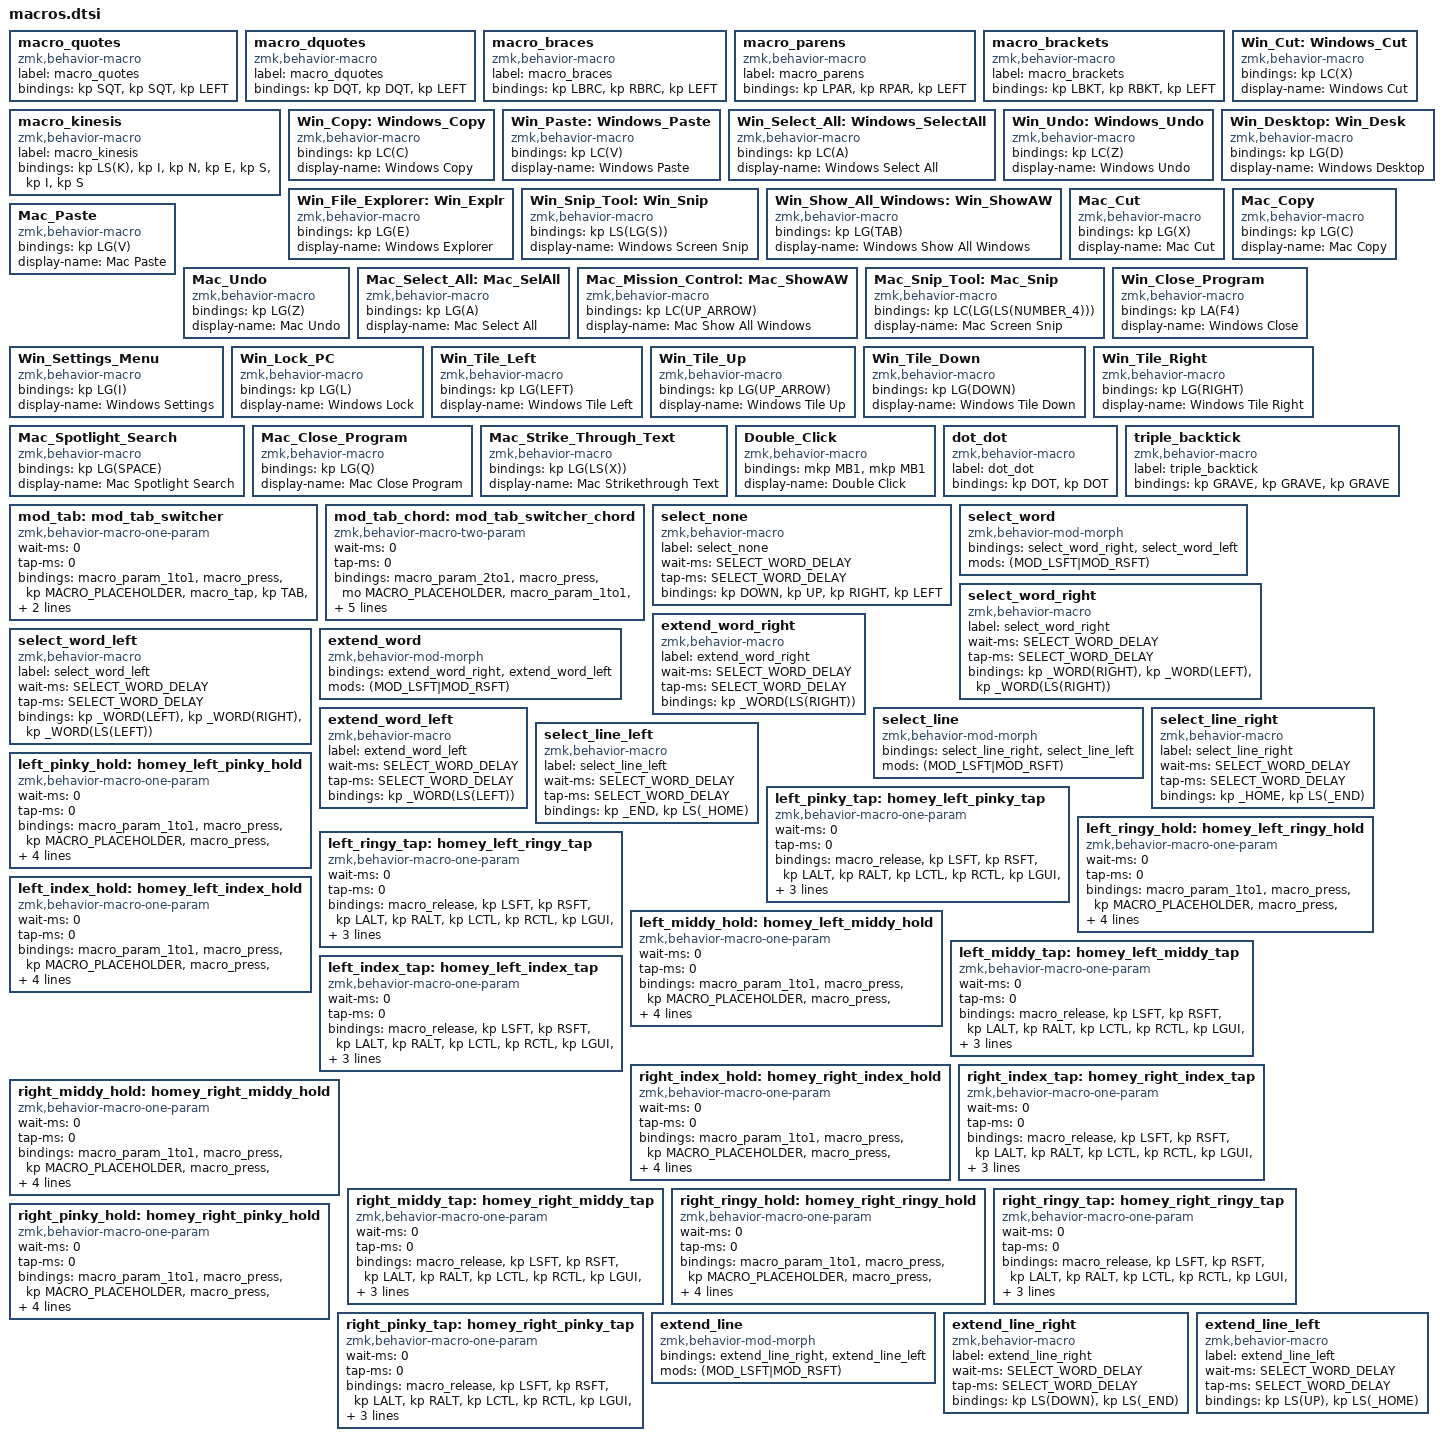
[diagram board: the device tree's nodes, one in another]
  macro_quotes: macro_quotes {
    compatible = "zmk,behavior-macro";
    label = "macro_quotes";
    #binding-cells = <0>;
    bindings = <&kp SQT>, <&kp SQT>, <&kp LEFT>;
  };

  macro_dquotes: macro_dquotes {
    compatible = "zmk,behavior-macro";
    label = "macro_dquotes";
    #binding-cells = <0>;
    bindings = <&kp DQT>, <&kp DQT>, <&kp LEFT>;
  };

  macro_braces: macro_braces {
    compatible = "zmk,behavior-macro";
    label = "macro_braces";
    #binding-cells = <0>;
    bindings = <&kp LBRC>, <&kp RBRC>, <&kp LEFT>;
  };

  macro_parens: macro_parens {
    compatible = "zmk,behavior-macro";
    label = "macro_parens";
    #binding-cells = <0>;
    bindings = <&kp LPAR>, <&kp RPAR>, <&kp LEFT>;
  };

  macro_brackets: macro_brackets {
    compatible = "zmk,behavior-macro";
    label = "macro_brackets";
    #binding-cells = <0>;
    bindings = <&kp LBKT>, <&kp RBKT>, <&kp LEFT>;
  };

  macro_kinesis: macro_kinesis {
    compatible = "zmk,behavior-macro";
    label = "macro_kinesis";
    #binding-cells = <0>;
    bindings = <&kp LS(K)>, <&kp I>, <&kp N>, <&kp E>, <&kp S>, <&kp I>, <&kp S>;
  };

  Win_Cut: Windows_Cut {
    compatible = "zmk,behavior-macro";
    #binding-cells = <0>;
    bindings = <&kp LC(X)>;
    display-name = "Windows Cut";
  };

  Win_Copy: Windows_Copy {
    compatible = "zmk,behavior-macro";
    #binding-cells = <0>;
    bindings = <&kp LC(C)>;
    display-name = "Windows Copy";
  };

  Win_Paste: Windows_Paste {
    compatible = "zmk,behavior-macro";
    #binding-cells = <0>;
    bindings = <&kp LC(V)>;
    display-name = "Windows Paste";
  };

  Win_Select_All: Windows_SelectAll {
      compatible = "zmk,behavior-macro";
      #binding-cells = <0>;
      bindings = <&kp LC(A)>;
      display-name = "Windows Select All";
  };

  Win_Undo: Windows_Undo {
    compatible = "zmk,behavior-macro";
    #binding-cells = <0>;
    bindings = <&kp LC(Z)>;
    display-name = "Windows Undo";
  };

  Win_Desktop: Win_Desk {
    compatible = "zmk,behavior-macro";
    #binding-cells = <0>;
    bindings = <&kp LG(D)>;
    display-name = "Windows Desktop";
  };

  Win_File_Explorer: Win_Explr {
    compatible = "zmk,behavior-macro";
    #binding-cells = <0>;
    bindings = <&kp LG(E)>;
    display-name = "Windows Explorer";
  };

  Win_Snip_Tool: Win_Snip {
    compatible = "zmk,behavior-macro";
    #binding-cells = <0>;
    bindings = <&kp LS(LG(S))>;
    display-name = "Windows Screen Snip";
  };

  Win_Show_All_Windows: Win_ShowAW {
    compatible = "zmk,behavior-macro";
    #binding-cells = <0>;
    bindings = <&kp LG(TAB)>;
    display-name = "Windows Show All Windows";
  };

  Mac_Cut: Mac_Cut {
    compatible = "zmk,behavior-macro";
    #binding-cells = <0>;
    bindings = <&kp LG(X)>;
    display-name = "Mac Cut";
  };

  Mac_Copy: Mac_Copy {
    compatible = "zmk,behavior-macro";
    #binding-cells = <0>;
    bindings = <&kp LG(C)>;
    display-name = "Mac Copy";
  };

  Mac_Paste: Mac_Paste {
    compatible = "zmk,behavior-macro";
    #binding-cells = <0>;
    bindings = <&kp LG(V)>;
    display-name = "Mac Paste";
  };

  Mac_Undo: Mac_Undo {
    compatible = "zmk,behavior-macro";
    #binding-cells = <0>;
    bindings = <&kp LG(Z)>;
    display-name = "Mac Undo";
  };

  Mac_Select_All: Mac_SelAll {
    compatible = "zmk,behavior-macro";
    #binding-cells = <0>;
    bindings = <&kp LG(A)>;
    display-name = "Mac Select All";
  };

  Mac_Mission_Control: Mac_ShowAW {
    compatible = "zmk,behavior-macro";
    #binding-cells = <0>;
    bindings = <&kp LC(UP_ARROW)>;
    display-name = "Mac Show All Windows";
  };

  Mac_Snip_Tool: Mac_Snip {
    compatible = "zmk,behavior-macro";
    #binding-cells = <0>;
    bindings = <&kp LC(LG(LS(NUMBER_4)))>;
    display-name = "Mac Screen Snip";
  };

  Win_Close_Program: Win_Close_Program {
    compatible = "zmk,behavior-macro";
    #binding-cells = <0>;
    bindings = <&kp LA(F4)>;
    display-name = "Windows Close";
  };

  Win_Settings_Menu: Win_Settings_Menu {
    compatible = "zmk,behavior-macro";
    #binding-cells = <0>;
    bindings = <&kp LG(I)>;
    display-name = "Windows Settings";
  };

  Win_Lock_PC: Win_Lock_PC {
    compatible = "zmk,behavior-macro";
    #binding-cells = <0>;
    bindings = <&kp LG(L)>;
    display-name = "Windows Lock";
  };

  Win_Tile_Left: Win_Tile_Left {
    compatible = "zmk,behavior-macro";
    #binding-cells = <0>;
    bindings = <&kp LG(LEFT)>;
    display-name = "Windows Tile Left";
  };

  Win_Tile_Up: Win_Tile_Up {
    compatible = "zmk,behavior-macro";
    #binding-cells = <0>;
    bindings = <&kp LG(UP_ARROW)>;
    display-name = "Windows Tile Up";
  };

  Win_Tile_Down: Win_Tile_Down {
    compatible = "zmk,behavior-macro";
    #binding-cells = <0>;
    bindings = <&kp LG(DOWN)>;
    display-name = "Windows Tile Down";
  };

  Win_Tile_Right: Win_Tile_Right {
    compatible = "zmk,behavior-macro";
    #binding-cells = <0>;
    bindings = <&kp LG(RIGHT)>;
    display-name = "Windows Tile Right";
  };

  Mac_Spotlight_Search: Mac_Spotlight_Search {
    compatible = "zmk,behavior-macro";
    #binding-cells = <0>;
    bindings = <&kp LG(SPACE)>;
    display-name = "Mac Spotlight Search";
  };

  Mac_Close_Program: Mac_Close_Program {
    compatible = "zmk,behavior-macro";
    #binding-cells = <0>;
    bindings = <&kp LG(Q)>;
    display-name = "Mac Close Program";
  };

  Mac_Strike_Through_Text: Mac_Strike_Through_Text {
    compatible = "zmk,behavior-macro";
    #binding-cells = <0>;
    bindings = <&kp LG(LS(X))>;
    display-name = "Mac Strikethrough Text";
  };

  Double_Click: Double_Click {
    compatible = "zmk,behavior-macro";
    #binding-cells = <0>;
    bindings = <&mkp MB1 &mkp MB1>;
    display-name = "Double Click";
  };

  dot_dot: dot_dot {
    compatible = "zmk,behavior-macro";
    label = "dot_dot";
    #binding-cells = <0>;
    bindings = <&kp DOT>, <&kp DOT>;
  };

  triple_backtick: triple_backtick {
    compatible = "zmk,behavior-macro";
    label = "triple_backtick";
    #binding-cells = <0>;
    bindings = <&kp GRAVE>, <&kp GRAVE>, <&kp GRAVE>;
  };

  // Mod+Tab application switcher — hold to keep menu open
  mod_tab: mod_tab_switcher {
    compatible = "zmk,behavior-macro-one-param";
    wait-ms = <0>;
    tap-ms = <0>;
    #binding-cells = <1>;
    bindings
      = <&macro_param_1to1>
      , <&macro_press &kp MACRO_PLACEHOLDER>
      , <&macro_tap &kp TAB>
      , <&macro_pause_for_release>
      , <&macro_param_1to1>
      , <&macro_release &kp MACRO_PLACEHOLDER>
      ;
  };
  mod_tab_chord: mod_tab_switcher_chord {
    compatible = "zmk,behavior-macro-two-param";
    wait-ms = <0>;
    tap-ms = <0>;
    #binding-cells = <2>;
    bindings
      = <&macro_param_2to1>
      , <&macro_press &mo MACRO_PLACEHOLDER>
      , <&macro_param_1to1>
      , <&macro_press &mod_tab MACRO_PLACEHOLDER>
      , <&macro_pause_for_release>
      , <&macro_param_1to1>
      , <&macro_release &mod_tab MACRO_PLACEHOLDER>
      , <&macro_param_2to1>
      , <&macro_release &mo MACRO_PLACEHOLDER>
      ;
  };

  // Select none (deselect)
  select_none: select_none {
    compatible = "zmk,behavior-macro";
    label = "select_none";
    wait-ms = <SELECT_WORD_DELAY>;
    tap-ms = <SELECT_WORD_DELAY>;
    #binding-cells = <0>;
    bindings = <&kp DOWN>, <&kp UP>, <&kp RIGHT>, <&kp LEFT>;
  };

  // Select word — shift inverts direction
  select_word: select_word {
    compatible = "zmk,behavior-mod-morph";
    #binding-cells = <0>;
    bindings = <&select_word_right>, <&select_word_left>;
    mods = <(MOD_LSFT|MOD_RSFT)>;
  };
  select_word_right: select_word_right {
    compatible = "zmk,behavior-macro";
    label = "select_word_right";
    wait-ms = <SELECT_WORD_DELAY>;
    tap-ms = <SELECT_WORD_DELAY>;
    #binding-cells = <0>;
    bindings = <&kp _WORD(RIGHT)>, <&kp _WORD(LEFT)>, <&kp _WORD(LS(RIGHT))>;
  };
  select_word_left: select_word_left {
    compatible = "zmk,behavior-macro";
    label = "select_word_left";
    wait-ms = <SELECT_WORD_DELAY>;
    tap-ms = <SELECT_WORD_DELAY>;
    #binding-cells = <0>;
    bindings = <&kp _WORD(LEFT)>, <&kp _WORD(RIGHT)>, <&kp _WORD(LS(LEFT))>;
  };

  // Extend word selection
  extend_word: extend_word {
    compatible = "zmk,behavior-mod-morph";
    #binding-cells = <0>;
    bindings = <&extend_word_right>, <&extend_word_left>;
    mods = <(MOD_LSFT|MOD_RSFT)>;
  };
  extend_word_right: extend_word_right {
    compatible = "zmk,behavior-macro";
    label = "extend_word_right";
    wait-ms = <SELECT_WORD_DELAY>;
    tap-ms = <SELECT_WORD_DELAY>;
    #binding-cells = <0>;
    bindings = <&kp _WORD(LS(RIGHT))>;
  };
  extend_word_left: extend_word_left {
    compatible = "zmk,behavior-macro";
    label = "extend_word_left";
    wait-ms = <SELECT_WORD_DELAY>;
    tap-ms = <SELECT_WORD_DELAY>;
    #binding-cells = <0>;
    bindings = <&kp _WORD(LS(LEFT))>;
  };

  // Select line
  select_line: select_line {
    compatible = "zmk,behavior-mod-morph";
    #binding-cells = <0>;
    bindings = <&select_line_right>, <&select_line_left>;
    mods = <(MOD_LSFT|MOD_RSFT)>;
  };
  select_line_right: select_line_right {
    compatible = "zmk,behavior-macro";
    label = "select_line_right";
    wait-ms = <SELECT_WORD_DELAY>;
    tap-ms = <SELECT_WORD_DELAY>;
    #binding-cells = <0>;
    bindings = <&kp _HOME>, <&kp LS(_END)>;
  };
  select_line_left: select_line_left {
    compatible = "zmk,behavior-macro";
    label = "select_line_left";
    wait-ms = <SELECT_WORD_DELAY>;
    tap-ms = <SELECT_WORD_DELAY>;
    #binding-cells = <0>;
    bindings = <&kp _END>, <&kp LS(_HOME)>;
  };

  //
  // Bilateral enforcement macros
  //
  // _hold macros: press modifier + activate bilateral enforcement layer
  // _tap macros: release all mods, tap home row key, tap parameter key
  //   (used on same-hand keys in bilateral layers to cancel the modifier)
  //

  // Left Pinky
  left_pinky_hold: homey_left_pinky_hold {
    compatible = "zmk,behavior-macro-one-param";
    wait-ms = <0>;
    tap-ms = <0>;
    #binding-cells = <1>;
    bindings
      = <&macro_param_1to1>
      , <&macro_press &kp MACRO_PLACEHOLDER>
      , <&macro_press &mo LAYER_LeftPinky>
      , <&macro_pause_for_release>
      , <&macro_param_1to1>
      , <&macro_release &kp MACRO_PLACEHOLDER>
      , <&macro_release &mo LAYER_LeftPinky>
      ;
  };
  left_pinky_tap: homey_left_pinky_tap {
    compatible = "zmk,behavior-macro-one-param";
    wait-ms = <0>;
    tap-ms = <0>;
    #binding-cells = <1>;
    bindings
      = <&macro_release
          &kp LSFT &kp RSFT
          &kp LALT &kp RALT
          &kp LCTL &kp RCTL
          &kp LGUI &kp RGUI>
      , <&macro_tap &kp LEFT_PINKY_TAP_KEY>
      , <&macro_param_1to1>
      , <&macro_tap &kp MACRO_PLACEHOLDER>
      ;
  };

  // Left Ringy
  left_ringy_hold: homey_left_ringy_hold {
    compatible = "zmk,behavior-macro-one-param";
    wait-ms = <0>;
    tap-ms = <0>;
    #binding-cells = <1>;
    bindings
      = <&macro_param_1to1>
      , <&macro_press &kp MACRO_PLACEHOLDER>
      , <&macro_press &mo LAYER_LeftRingy>
      , <&macro_pause_for_release>
      , <&macro_param_1to1>
      , <&macro_release &kp MACRO_PLACEHOLDER>
      , <&macro_release &mo LAYER_LeftRingy>
      ;
  };
  left_ringy_tap: homey_left_ringy_tap {
    compatible = "zmk,behavior-macro-one-param";
    wait-ms = <0>;
    tap-ms = <0>;
    #binding-cells = <1>;
    bindings
      = <&macro_release
          &kp LSFT &kp RSFT
          &kp LALT &kp RALT
          &kp LCTL &kp RCTL
          &kp LGUI &kp RGUI>
      , <&macro_tap &kp LEFT_RINGY_TAP_KEY>
      , <&macro_param_1to1>
      , <&macro_tap &kp MACRO_PLACEHOLDER>
      ;
  };

  // Left Middy
  left_middy_hold: homey_left_middy_hold {
    compatible = "zmk,behavior-macro-one-param";
    wait-ms = <0>;
    tap-ms = <0>;
    #binding-cells = <1>;
    bindings
      = <&macro_param_1to1>
      , <&macro_press &kp MACRO_PLACEHOLDER>
      , <&macro_press &mo LAYER_LeftMiddy>
      , <&macro_pause_for_release>
      , <&macro_param_1to1>
      , <&macro_release &kp MACRO_PLACEHOLDER>
      , <&macro_release &mo LAYER_LeftMiddy>
      ;
  };
  left_middy_tap: homey_left_middy_tap {
    compatible = "zmk,behavior-macro-one-param";
    wait-ms = <0>;
    tap-ms = <0>;
    #binding-cells = <1>;
    bindings
      = <&macro_release
          &kp LSFT &kp RSFT
          &kp LALT &kp RALT
          &kp LCTL &kp RCTL
          &kp LGUI &kp RGUI>
      , <&macro_tap &kp LEFT_MIDDY_TAP_KEY>
      , <&macro_param_1to1>
      , <&macro_tap &kp MACRO_PLACEHOLDER>
      ;
  };

  // Left Index
  left_index_hold: homey_left_index_hold {
    compatible = "zmk,behavior-macro-one-param";
    wait-ms = <0>;
    tap-ms = <0>;
    #binding-cells = <1>;
    bindings
      = <&macro_param_1to1>
      , <&macro_press &kp MACRO_PLACEHOLDER>
      , <&macro_press &mo LAYER_LeftIndex>
      , <&macro_pause_for_release>
      , <&macro_param_1to1>
      , <&macro_release &kp MACRO_PLACEHOLDER>
      , <&macro_release &mo LAYER_LeftIndex>
      ;
  };
  left_index_tap: homey_left_index_tap {
    compatible = "zmk,behavior-macro-one-param";
    wait-ms = <0>;
    tap-ms = <0>;
    #binding-cells = <1>;
    bindings
      = <&macro_release
          &kp LSFT &kp RSFT
          &kp LALT &kp RALT
          &kp LCTL &kp RCTL
          &kp LGUI &kp RGUI>
      , <&macro_tap &kp LEFT_INDEX_TAP_KEY>
      , <&macro_param_1to1>
      , <&macro_tap &kp MACRO_PLACEHOLDER>
      ;
  };

  // Right Index
  right_index_hold: homey_right_index_hold {
    compatible = "zmk,behavior-macro-one-param";
    wait-ms = <0>;
    tap-ms = <0>;
    #binding-cells = <1>;
    bindings
      = <&macro_param_1to1>
      , <&macro_press &kp MACRO_PLACEHOLDER>
      , <&macro_press &mo LAYER_RightIndex>
      , <&macro_pause_for_release>
      , <&macro_param_1to1>
      , <&macro_release &kp MACRO_PLACEHOLDER>
      , <&macro_release &mo LAYER_RightIndex>
      ;
  };
  right_index_tap: homey_right_index_tap {
    compatible = "zmk,behavior-macro-one-param";
    wait-ms = <0>;
    tap-ms = <0>;
    #binding-cells = <1>;
    bindings
      = <&macro_release
          &kp LSFT &kp RSFT
          &kp LALT &kp RALT
          &kp LCTL &kp RCTL
          &kp LGUI &kp RGUI>
      , <&macro_tap &kp RIGHT_INDEX_TAP_KEY>
      , <&macro_param_1to1>
      , <&macro_tap &kp MACRO_PLACEHOLDER>
      ;
  };

  // Right Middy
  right_middy_hold: homey_right_middy_hold {
    compatible = "zmk,behavior-macro-one-param";
    wait-ms = <0>;
    tap-ms = <0>;
    #binding-cells = <1>;
    bindings
      = <&macro_param_1to1>
      , <&macro_press &kp MACRO_PLACEHOLDER>
      , <&macro_press &mo LAYER_RightMiddy>
      , <&macro_pause_for_release>
      , <&macro_param_1to1>
      , <&macro_release &kp MACRO_PLACEHOLDER>
      , <&macro_release &mo LAYER_RightMiddy>
      ;
  };
  right_middy_tap: homey_right_middy_tap {
    compatible = "zmk,behavior-macro-one-param";
    wait-ms = <0>;
    tap-ms = <0>;
    #binding-cells = <1>;
    bindings
      = <&macro_release
          &kp LSFT &kp RSFT
          &kp LALT &kp RALT
          &kp LCTL &kp RCTL
          &kp LGUI &kp RGUI>
      , <&macro_tap &kp RIGHT_MIDDY_TAP_KEY>
      , <&macro_param_1to1>
      , <&macro_tap &kp MACRO_PLACEHOLDER>
      ;
  };

  // Right Ringy
  right_ringy_hold: homey_right_ringy_hold {
    compatible = "zmk,behavior-macro-one-param";
    wait-ms = <0>;
    tap-ms = <0>;
    #binding-cells = <1>;
    bindings
      = <&macro_param_1to1>
      , <&macro_press &kp MACRO_PLACEHOLDER>
      , <&macro_press &mo LAYER_RightRingy>
      , <&macro_pause_for_release>
      , <&macro_param_1to1>
      , <&macro_release &kp MACRO_PLACEHOLDER>
      , <&macro_release &mo LAYER_RightRingy>
      ;
  };
  right_ringy_tap: homey_right_ringy_tap {
    compatible = "zmk,behavior-macro-one-param";
    wait-ms = <0>;
    tap-ms = <0>;
    #binding-cells = <1>;
    bindings
      = <&macro_release
          &kp LSFT &kp RSFT
          &kp LALT &kp RALT
          &kp LCTL &kp RCTL
          &kp LGUI &kp RGUI>
      , <&macro_tap &kp RIGHT_RINGY_TAP_KEY>
      , <&macro_param_1to1>
      , <&macro_tap &kp MACRO_PLACEHOLDER>
      ;
  };

  // Right Pinky
  right_pinky_hold: homey_right_pinky_hold {
    compatible = "zmk,behavior-macro-one-param";
    wait-ms = <0>;
    tap-ms = <0>;
    #binding-cells = <1>;
    bindings
      = <&macro_param_1to1>
      , <&macro_press &kp MACRO_PLACEHOLDER>
      , <&macro_press &mo LAYER_RightPinky>
      , <&macro_pause_for_release>
      , <&macro_param_1to1>
      , <&macro_release &kp MACRO_PLACEHOLDER>
      , <&macro_release &mo LAYER_RightPinky>
      ;
  };
  right_pinky_tap: homey_right_pinky_tap {
    compatible = "zmk,behavior-macro-one-param";
    wait-ms = <0>;
    tap-ms = <0>;
    #binding-cells = <1>;
    bindings
      = <&macro_release
          &kp LSFT &kp RSFT
          &kp LALT &kp RALT
          &kp LCTL &kp RCTL
          &kp LGUI &kp RGUI>
      , <&macro_tap &kp RIGHT_PINKY_TAP_KEY>
      , <&macro_param_1to1>
      , <&macro_tap &kp MACRO_PLACEHOLDER>
      ;
  };

  // Extend line selection
  extend_line: extend_line {
    compatible = "zmk,behavior-mod-morph";
    #binding-cells = <0>;
    bindings = <&extend_line_right>, <&extend_line_left>;
    mods = <(MOD_LSFT|MOD_RSFT)>;
  };
  extend_line_right: extend_line_right {
    compatible = "zmk,behavior-macro";
    label = "extend_line_right";
    wait-ms = <SELECT_WORD_DELAY>;
    tap-ms = <SELECT_WORD_DELAY>;
    #binding-cells = <0>;
    bindings = <&kp LS(DOWN)>, <&kp LS(_END)>;
  };
  extend_line_left: extend_line_left {
    compatible = "zmk,behavior-macro";
    label = "extend_line_left";
    wait-ms = <SELECT_WORD_DELAY>;
    tap-ms = <SELECT_WORD_DELAY>;
    #binding-cells = <0>;
    bindings = <&kp LS(UP)>, <&kp LS(_HOME)>;
  };
